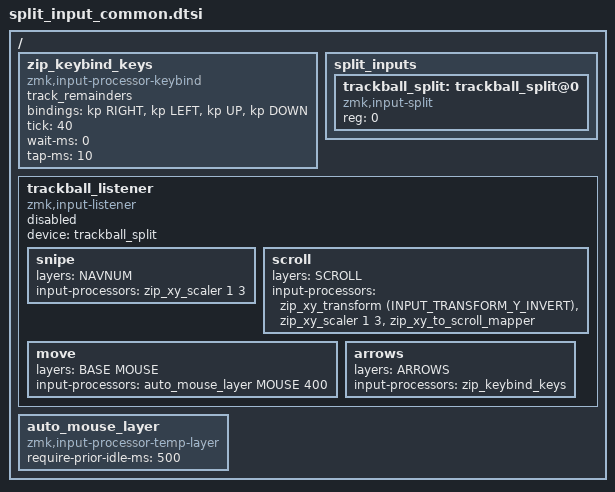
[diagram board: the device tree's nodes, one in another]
#include <dt-bindings/zmk/input_transform.h>
#include <input/processors.dtsi>
#include <dt-bindings/zmk/keys.h>

#define BASE 0
#define NAVNUM 1
#define SYMBOL 2
#define MEDIA 3
#define MOUSE 4
#define SCROLL 5
#define ARROWS 6

/ {
  zip_keybind_keys: zip_keybind_keys {
    compatible = "zmk,input-processor-keybind";
    #input-processor-cells = <0>;
    track_remainders;
    bindings = <&kp RIGHT>, <&kp LEFT>, <&kp UP>, <&kp DOWN>;
    tick = <40>;
    wait-ms = <0>;
    tap-ms = <10>;
  };

  split_inputs {
    #address-cells = <1>;
    #size-cells = <0>;

    trackball_split: trackball_split@0 {
      compatible = "zmk,input-split";
      reg = <0>;
    };
  };

  trackball_listener: trackball_listener {
    compatible = "zmk,input-listener";
    status = "disabled";
    device = <&trackball_split>;

    snipe {
      layers = <NAVNUM>;
      input-processors = <&zip_xy_scaler 1 3>;
    };

    scroll {
      layers = <SCROLL>;
      input-processors = <&zip_xy_transform (INPUT_TRANSFORM_Y_INVERT)>, <&zip_xy_scaler 1 3>, <&zip_xy_to_scroll_mapper>;
    };

    move {
      layers = <BASE MOUSE>;
      input-processors = <&auto_mouse_layer MOUSE 400>;
    };

    arrows {
      layers = <ARROWS>;
      input-processors = <&zip_keybind_keys>;
    };
  };

  auto_mouse_layer: auto_mouse_layer {
    compatible = "zmk,input-processor-temp-layer";
    #input-processor-cells = <2>;
    require-prior-idle-ms = <500>;
  };
};

